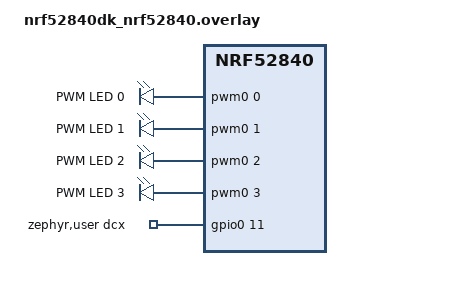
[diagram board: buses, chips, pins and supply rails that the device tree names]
/ {
    pwmleds {
        compatible = "pwm-leds";
        pwm_led0: pwm_led_0 {
            pwms = <&pwm0 0 PWM_MSEC(20) PWM_POLARITY_NORMAL>;
            label = "PWM LED 0";
        };
        pwm_led1: pwm_led_1 {
            pwms = <&pwm0 1 PWM_MSEC(20) PWM_POLARITY_NORMAL>;
            label = "PWM LED 1";
        };
        pwm_led2: pwm_led_2 {
            pwms = <&pwm0 2 PWM_MSEC(20) PWM_POLARITY_NORMAL>;
            label = "PWM LED 2";
        };
        pwm_led3: pwm_led_3 {
            pwms = <&pwm0 3 PWM_MSEC(20) PWM_POLARITY_NORMAL>;
            label = "PWM LED 3";
        };
    };

    zephyr,user {
        dcx_gpios = <&gpio0 11 GPIO_ACTIVE_HIGH>;
    };

    aliases {
        pwm-led0 = &pwm_led0;
        pwm-led1 = &pwm_led1;
        pwm-led2 = &pwm_led2;
        pwm-led3 = &pwm_led3;
    };
};

&arduino_spi {
    cs-gpios = <&gpio1 12 GPIO_ACTIVE_LOW>;
};
